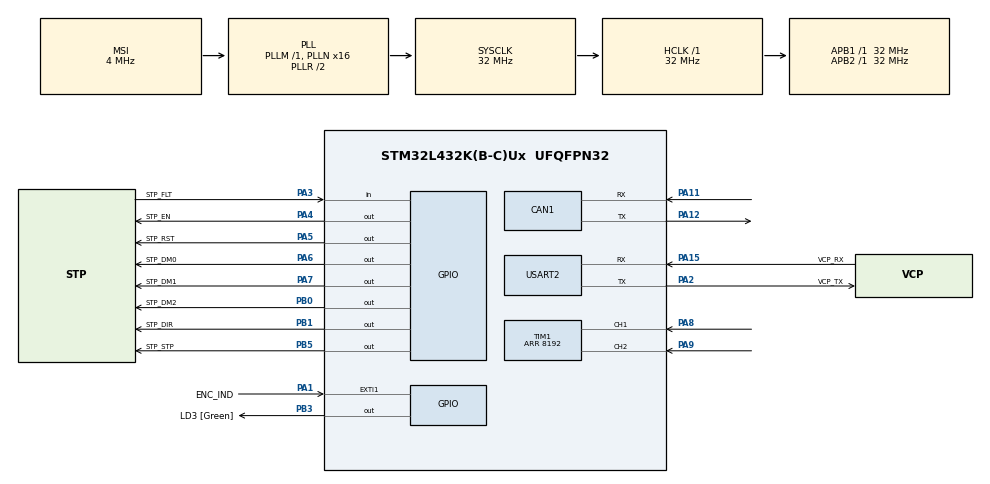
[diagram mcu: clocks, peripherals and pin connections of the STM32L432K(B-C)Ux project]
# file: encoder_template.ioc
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CAN1.CalculateTimeQuantum=500.0
Mcu.Family=STM32L4
Mcu.Name=STM32L432K(B-C)Ux
Mcu.Package=UFQFPN32
NVIC.PriorityGroup=NVIC_PRIORITYGROUP_4
NVIC.TIM7_IRQn=true\:0\:0\:false\:false\:true\:true
PA0.GPIO_Label=MCO [High speed clock in]
PA0.Mode=HSE-External-Clock-Source-for-LittleOrca
PA0.Signal=RCC_CK_IN
PA1.GPIO_Label=ENC_IND
PA1.Signal=GPXTI1
PA11.Mode=Master
PA11.Signal=CAN1_RX
PA12.Mode=Master
PA12.Signal=CAN1_TX
PA13\ (JTMS-SWDIO).GPIO_Label=SWDIO
PA13\ (JTMS-SWDIO).Mode=Serial_Wire
PA13\ (JTMS-SWDIO).Signal=SYS_JTMS-SWDIO
PA14\ (JTCK-SWCLK).GPIO_Label=SWCLK
PA14\ (JTCK-SWCLK).Mode=Serial_Wire
PA14\ (JTCK-SWCLK).Signal=SYS_JTCK-SWCLK
PA15\ (JTDI).GPIO_Label=VCP_RX
PA15\ (JTDI).Mode=Asynchronous
PA15\ (JTDI).Signal=USART2_RX
PA2.GPIO_Label=VCP_TX
PA2.Mode=Asynchronous
PA2.Signal=USART2_TX
PA3.GPIO_Label=STP_FLT
PA3.Signal=GPIO_Input
PA4.GPIO_Label=STP_EN
PA4.Signal=GPIO_Output
PA5.GPIO_Label=STP_RST
PA5.Signal=GPIO_Output
PA6.GPIO_Label=STP_DM0
PA6.Signal=GPIO_Output
PA7.GPIO_Label=STP_DM1
PA7.Signal=GPIO_Output
PA8.Signal=S_TIM1_CH1
PA9.Signal=S_TIM1_CH2
PB0.GPIO_Label=STP_DM2
PB0.Signal=GPIO_Output
PB1.GPIO_Label=STP_DIR
PB1.Signal=GPIO_Output
PB3\ (JTDO-TRACESWO).GPIO_Label=LD3 [Green]
PB3\ (JTDO-TRACESWO).Signal=GPIO_Output
PB5.GPIO_Label=STP_STP
PB5.Signal=GPIO_Output
PC14-OSC32_IN\ (PC14).Mode=LSE-External-Oscillator
PC14-OSC32_IN\ (PC14).Signal=RCC_OSC32_IN
PC15-OSC32_OUT\ (PC15).Mode=LSE-External-Oscillator
PC15-OSC32_OUT\ (PC15).Signal=RCC_OSC32_OUT
ProjectManager.HeapSize=0x200
ProjectManager.StackSize=0x400
ProjectManager.TargetToolchain=TrueSTUDIO
RCC.AHBFreq_Value=32000000
RCC.APB1Freq_Value=32000000
RCC.APB1TimFreq_Value=32000000
RCC.APB2Freq_Value=32000000
RCC.APB2TimFreq_Value=32000000
RCC.CortexFreq_Value=32000000
RCC.HCLKFreq_Value=32000000
RCC.HSE_VALUE=8000000
RCC.HSI16_VALUE=16000000
RCC.HSI48_VALUE=48000000
RCC.HSI_VALUE=16000000
RCC.MSI_VALUE=4000000
RCC.PLLMUL=RCC_PLLMUL_4
RCC.PLLN=16
RCC.SYSCLKFreq_VALUE=32000000
RCC.SYSCLKSource=RCC_SYSCLKSOURCE_PLLCLK
RCC.VCOOutputFreq_Value=64000000
SH.S_TIM1_CH1.0=TIM1_CH1,Encoder_Interface
SH.S_TIM1_CH2.0=TIM1_CH2,Encoder_Interface
TIM1.Period=8192
TIM7.Period=0xffff
USART2.VirtualMode-Asynchronous=VM_ASYNC
VP_TIM7_VS_ClockSourceINT.Mode=Enable_Timer
board=NUCLEO-L432KC

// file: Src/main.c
/* USER CODE BEGIN Header */
/**
  ******************************************************************************
  * @file           : main.c
  * @brief          : Main program body
  ******************************************************************************
  ** This notice applies to any and all portions of this file
  * that are not between comment pairs USER CODE BEGIN and
  * USER CODE END. Other portions of this file, whether
  * inserted by the user or by software development tools
  * are owned by their respective copyright owners.
  *
  * COPYRIGHT(c) 2019 STMicroelectronics
  *
  * Redistribution and use in source and binary forms, with or without modification,
  * are permitted provided that the following conditions are met:
  *   1. Redistributions of source code must retain the above copyright notice,
  *      this list of conditions and the following disclaimer.
  *   2. Redistributions in binary form must reproduce the above copyright notice,
  *      this list of conditions and the following disclaimer in the documentation
  *      and/or other materials provided with the distribution.
  *   3. Neither the name of STMicroelectronics nor the names of its contributors
  *      may be used to endorse or promote products derived from this software
  *      without specific prior written permission.
  *
  * THIS SOFTWARE IS PROVIDED BY THE COPYRIGHT HOLDERS AND CONTRIBUTORS "AS IS"
  * AND ANY EXPRESS OR IMPLIED WARRANTIES, INCLUDING, BUT NOT LIMITED TO, THE
  * IMPLIED WARRANTIES OF MERCHANTABILITY AND FITNESS FOR A PARTICULAR PURPOSE ARE
  * DISCLAIMED. IN NO EVENT SHALL THE COPYRIGHT HOLDER OR CONTRIBUTORS BE LIABLE
  * FOR ANY DIRECT, INDIRECT, INCIDENTAL, SPECIAL, EXEMPLARY, OR CONSEQUENTIAL
  * DAMAGES (INCLUDING, BUT NOT LIMITED TO, PROCUREMENT OF SUBSTITUTE GOODS OR
  * SERVICES; LOSS OF USE, DATA, OR PROFITS; OR BUSINESS INTERRUPTION) HOWEVER
  * CAUSED AND ON ANY THEORY OF LIABILITY, WHETHER IN CONTRACT, STRICT LIABILITY,
  * OR TORT (INCLUDING NEGLIGENCE OR OTHERWISE) ARISING IN ANY WAY OUT OF THE USE
  * OF THIS SOFTWARE, EVEN IF ADVISED OF THE POSSIBILITY OF SUCH DAMAGE.
  *
  ******************************************************************************
  */
/* USER CODE END Header */

#include "main.h"

CAN_HandleTypeDef hcan1;

TIM_HandleTypeDef htim1;
TIM_HandleTypeDef htim7;

UART_HandleTypeDef huart2;

void SystemClock_Config(void);
static void MX_GPIO_Init(void);
static void MX_USART2_UART_Init(void);
static void MX_TIM1_Init(void);
static void MX_TIM7_Init(void);
static void MX_CAN1_Init(void);

int main(void)
{

  /* MCU Configuration--------------------------------------------------------*/

  /* Reset of all peripherals, Initializes the Flash interface and the Systick. */
  HAL_Init();

  /* Configure the system clock */
  SystemClock_Config();

  /* Initialize all configured peripherals */
  MX_GPIO_Init();
  MX_USART2_UART_Init();
  MX_TIM1_Init();
  MX_TIM7_Init();
  MX_CAN1_Init();
  /* USER CODE BEGIN 2 */
  HAL_TIM_Encoder_Start(&htim1, TIM_CHANNEL_ALL);
  HAL_NVIC_SetPriority(EXTI1_IRQn, 2, 0);
  HAL_NVIC_EnableIRQ(EXTI1_IRQn);

  /* USER CODE END 2 */

  /* Infinite loop */
  while (1)
  {

  }
}

void SystemClock_Config(void)
{
  RCC_OscInitTypeDef RCC_OscInitStruct = {0};
  RCC_ClkInitTypeDef RCC_ClkInitStruct = {0};
  RCC_PeriphCLKInitTypeDef PeriphClkInit = {0};

  /**Configure LSE Drive Capability
  */
  HAL_PWR_EnableBkUpAccess();
  __HAL_RCC_LSEDRIVE_CONFIG(RCC_LSEDRIVE_LOW);
  /**Initializes the CPU, AHB and APB busses clocks
  */
  RCC_OscInitStruct.OscillatorType = RCC_OSCILLATORTYPE_LSE|RCC_OSCILLATORTYPE_MSI;
  RCC_OscInitStruct.LSEState = RCC_LSE_ON;
  RCC_OscInitStruct.MSIState = RCC_MSI_ON;
  RCC_OscInitStruct.MSICalibrationValue = 0;
  RCC_OscInitStruct.MSIClockRange = RCC_MSIRANGE_6;
  RCC_OscInitStruct.PLL.PLLState = RCC_PLL_ON;
  RCC_OscInitStruct.PLL.PLLSource = RCC_PLLSOURCE_MSI;
  RCC_OscInitStruct.PLL.PLLM = 1;
  RCC_OscInitStruct.PLL.PLLN = 16;
  RCC_OscInitStruct.PLL.PLLP = RCC_PLLP_DIV7;
  RCC_OscInitStruct.PLL.PLLQ = RCC_PLLQ_DIV2;
  RCC_OscInitStruct.PLL.PLLR = RCC_PLLR_DIV2;
  if (HAL_RCC_OscConfig(&RCC_OscInitStruct) != HAL_OK)
  {
    Error_Handler();
  }
  /**Initializes the CPU, AHB and APB busses clocks
  */
  RCC_ClkInitStruct.ClockType = RCC_CLOCKTYPE_HCLK|RCC_CLOCKTYPE_SYSCLK
                              |RCC_CLOCKTYPE_PCLK1|RCC_CLOCKTYPE_PCLK2;
  RCC_ClkInitStruct.SYSCLKSource = RCC_SYSCLKSOURCE_PLLCLK;
  RCC_ClkInitStruct.AHBCLKDivider = RCC_SYSCLK_DIV1;
  RCC_ClkInitStruct.APB1CLKDivider = RCC_HCLK_DIV1;
  RCC_ClkInitStruct.APB2CLKDivider = RCC_HCLK_DIV1;

  if (HAL_RCC_ClockConfig(&RCC_ClkInitStruct, FLASH_LATENCY_1) != HAL_OK)
  {
    Error_Handler();
  }
  PeriphClkInit.PeriphClockSelection = RCC_PERIPHCLK_USART2;
  PeriphClkInit.Usart2ClockSelection = RCC_USART2CLKSOURCE_PCLK1;
  if (HAL_RCCEx_PeriphCLKConfig(&PeriphClkInit) != HAL_OK)
  {
    Error_Handler();
  }
  /**Configure the main internal regulator output voltage
  */
  if (HAL_PWREx_ControlVoltageScaling(PWR_REGULATOR_VOLTAGE_SCALE1) != HAL_OK)
  {
    Error_Handler();
  }
  /**Enable MSI Auto calibration
  */
  HAL_RCCEx_EnableMSIPLLMode();
}

static void MX_CAN1_Init(void)
{

  hcan1.Instance = CAN1;
  hcan1.Init.Prescaler = 16;
  hcan1.Init.Mode = CAN_MODE_NORMAL;
  hcan1.Init.SyncJumpWidth = CAN_SJW_1TQ;
  hcan1.Init.TimeSeg1 = CAN_BS1_1TQ;
  hcan1.Init.TimeSeg2 = CAN_BS2_1TQ;
  hcan1.Init.TimeTriggeredMode = DISABLE;
  hcan1.Init.AutoBusOff = DISABLE;
  hcan1.Init.AutoWakeUp = DISABLE;
  hcan1.Init.AutoRetransmission = DISABLE;
  hcan1.Init.ReceiveFifoLocked = DISABLE;
  hcan1.Init.TransmitFifoPriority = DISABLE;
  if (HAL_CAN_Init(&hcan1) != HAL_OK)
  {
    Error_Handler();
  }

}

static void MX_TIM1_Init(void)
{

  TIM_Encoder_InitTypeDef sConfig = {0};
  TIM_MasterConfigTypeDef sMasterConfig = {0};

  htim1.Instance = TIM1;
  htim1.Init.Prescaler = 0;
  htim1.Init.CounterMode = TIM_COUNTERMODE_UP;
  htim1.Init.Period = 8192;
  htim1.Init.ClockDivision = TIM_CLOCKDIVISION_DIV1;
  htim1.Init.RepetitionCounter = 0;
  htim1.Init.AutoReloadPreload = TIM_AUTORELOAD_PRELOAD_DISABLE;
  sConfig.EncoderMode = TIM_ENCODERMODE_TI1;
  sConfig.IC1Polarity = TIM_ICPOLARITY_RISING;
  sConfig.IC1Selection = TIM_ICSELECTION_DIRECTTI;
  sConfig.IC1Prescaler = TIM_ICPSC_DIV1;
  sConfig.IC1Filter = 0;
  sConfig.IC2Polarity = TIM_ICPOLARITY_RISING;
  sConfig.IC2Selection = TIM_ICSELECTION_DIRECTTI;
  sConfig.IC2Prescaler = TIM_ICPSC_DIV1;
  sConfig.IC2Filter = 0;
  if (HAL_TIM_Encoder_Init(&htim1, &sConfig) != HAL_OK)
  {
    Error_Handler();
  }
  sMasterConfig.MasterOutputTrigger = TIM_TRGO_RESET;
  sMasterConfig.MasterOutputTrigger2 = TIM_TRGO2_RESET;
  sMasterConfig.MasterSlaveMode = TIM_MASTERSLAVEMODE_DISABLE;
  if (HAL_TIMEx_MasterConfigSynchronization(&htim1, &sMasterConfig) != HAL_OK)
  {
    Error_Handler();
  }

}

static void MX_TIM7_Init(void)
{

  TIM_MasterConfigTypeDef sMasterConfig = {0};

  htim7.Instance = TIM7;
  htim7.Init.Prescaler = 0;
  htim7.Init.CounterMode = TIM_COUNTERMODE_UP;
  htim7.Init.Period = 0xffff;
  htim7.Init.AutoReloadPreload = TIM_AUTORELOAD_PRELOAD_DISABLE;
  if (HAL_TIM_Base_Init(&htim7) != HAL_OK)
  {
    Error_Handler();
  }
  sMasterConfig.MasterOutputTrigger = TIM_TRGO_RESET;
  sMasterConfig.MasterSlaveMode = TIM_MASTERSLAVEMODE_DISABLE;
  if (HAL_TIMEx_MasterConfigSynchronization(&htim7, &sMasterConfig) != HAL_OK)
  {
    Error_Handler();
  }

}

static void MX_USART2_UART_Init(void)
{

  huart2.Instance = USART2;
  huart2.Init.BaudRate = 115200;
  huart2.Init.WordLength = UART_WORDLENGTH_8B;
  huart2.Init.StopBits = UART_STOPBITS_1;
  huart2.Init.Parity = UART_PARITY_NONE;
  huart2.Init.Mode = UART_MODE_TX_RX;
  huart2.Init.HwFlowCtl = UART_HWCONTROL_NONE;
  huart2.Init.OverSampling = UART_OVERSAMPLING_16;
  huart2.Init.OneBitSampling = UART_ONE_BIT_SAMPLE_DISABLE;
  huart2.AdvancedInit.AdvFeatureInit = UART_ADVFEATURE_NO_INIT;
  if (HAL_UART_Init(&huart2) != HAL_OK)
  {
    Error_Handler();
  }

}

static void MX_GPIO_Init(void)
{
  GPIO_InitTypeDef GPIO_InitStruct = {0};

  /* GPIO Ports Clock Enable */
  __HAL_RCC_GPIOC_CLK_ENABLE();
  __HAL_RCC_GPIOA_CLK_ENABLE();
  __HAL_RCC_GPIOB_CLK_ENABLE();

  /*Configure GPIO pin Output Level */
  HAL_GPIO_WritePin(GPIOA, STP_EN_Pin|STP_RST_Pin|STP_DM0_Pin|STP_DM1_Pin, GPIO_PIN_RESET);

  /*Configure GPIO pin Output Level */
  HAL_GPIO_WritePin(GPIOB, STP_DM2_Pin|STP_DIR_Pin|LD3_Pin|STP_STP_Pin, GPIO_PIN_RESET);

  /*Configure GPIO pin : ENC_IND_Pin */
  GPIO_InitStruct.Pin = ENC_IND_Pin;
  GPIO_InitStruct.Mode = GPIO_MODE_IT_RISING;
  GPIO_InitStruct.Pull = GPIO_NOPULL;
  HAL_GPIO_Init(ENC_IND_GPIO_Port, &GPIO_InitStruct);

  /*Configure GPIO pin : STP_FLT_Pin */
  GPIO_InitStruct.Pin = STP_FLT_Pin;
  GPIO_InitStruct.Mode = GPIO_MODE_INPUT;
  GPIO_InitStruct.Pull = GPIO_NOPULL;
  HAL_GPIO_Init(STP_FLT_GPIO_Port, &GPIO_InitStruct);

  /*Configure GPIO pins : STP_EN_Pin STP_RST_Pin STP_DM0_Pin STP_DM1_Pin */
  GPIO_InitStruct.Pin = STP_EN_Pin|STP_RST_Pin|STP_DM0_Pin|STP_DM1_Pin;
  GPIO_InitStruct.Mode = GPIO_MODE_OUTPUT_PP;
  GPIO_InitStruct.Pull = GPIO_NOPULL;
  GPIO_InitStruct.Speed = GPIO_SPEED_FREQ_LOW;
  HAL_GPIO_Init(GPIOA, &GPIO_InitStruct);

  /*Configure GPIO pins : STP_DM2_Pin STP_DIR_Pin LD3_Pin STP_STP_Pin */
  GPIO_InitStruct.Pin = STP_DM2_Pin|STP_DIR_Pin|LD3_Pin|STP_STP_Pin;
  GPIO_InitStruct.Mode = GPIO_MODE_OUTPUT_PP;
  GPIO_InitStruct.Pull = GPIO_NOPULL;
  GPIO_InitStruct.Speed = GPIO_SPEED_FREQ_LOW;
  HAL_GPIO_Init(GPIOB, &GPIO_InitStruct);

}

void Error_Handler(void)
{
}

/************************ (C) COPYRIGHT STMicroelectronics *****END OF FILE****/
